# apb_ascon: IP-XACT component
VLNV emse.fr:ip:apb_ascon:0.2
Cryptographic accelerator for the Ascon128 AEAD authenticated encryption scheme.

## Parameters
APB_DW = 32
APB_AW = 10
FifoDepth = 4
DataAddrWidth = 7
DelayWidth = 16

## Bus interfaces (logical=physical port)
Clock: target tuni.fi:interface:clock:1.0
  clk=clk_in
IRQ: initiator tuni.fi:interface:IRQ:1.0
  irq=irq_1
APB: target tuni.fi:interface:APB:1.0
  PADDR=PADDR, PENABLE=PENABLE, PRDATA=PRDATA, PREADY=PREADY, PSEL=PSEL, PSLVERR=PSLVERR, PWDATA=PWDATA, PWRITE=PWRITE
Reset: target tuni.fi:interface:reset:1.0
  reset=reset_int
ss_ctrl: target tuni.fi:interface:SS_Ctrl:1.0
  clk_ctrl=ss_ctrl_1, irq_en=irq_en_1
pmod_gpio_0: initiator tuni.fi:interface:GPIO:1.0
  gpo=pmod_0_gpo, gpi=pmod_0_gpi, gpio_oe=pmod_0_gpio_oe
pmod_gpio_1: initiator tuni.fi:interface:GPIO:1.0
  gpo=pmod_1_gpo, gpi=pmod_1_gpi, gpio_oe=pmod_1_gpio_oe

## Ports
in clk_in
out irq_1
in PADDR[APB_AW-1:0]
in PENABLE
out PRDATA[APB_DW-1:0]
out PREADY
in PSEL
out PSLVERR
in PWDATA[APB_DW-1:0]
in PWRITE
in reset_int
in ss_ctrl_1[7:0]
in irq_en_1
out pmod_0_gpo[3:0]
in pmod_0_gpi[3:0]
out pmod_0_gpio_oe[3:0]
out pmod_1_gpo[3:0]
in pmod_1_gpi[3:0]
out pmod_1_gpio_oe[3:0]

## Address spaces and blocks
apb_ascon.registers: base 'h0, range 80, width 32

## Registers
Registers are 32-bit, read-write, no defined reset value unless marked. A register's access mark holds for its fields unless they carry their own. Offsets are from the block's base; lines under a group give offsets from that group; [hi:lo] are bit positions; {n}, {i} and the like mark numbered series; 'fields as' and 'values as' point back to an identical list; <NAME> marks a mode.

## apb_ascon.registers
Base 0x00000000
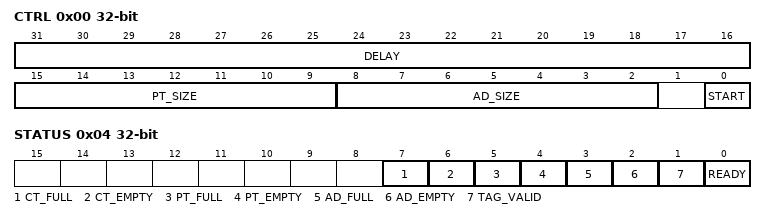
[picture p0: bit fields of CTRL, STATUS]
0x00 CTRL
  [31:16] DELAY, [15:9] PT_SIZE, [8:2] AD_SIZE, [0] START wo
0x04 STATUS ro
  [7] CT_FULL, [6] CT_EMPTY, [5] PT_FULL, [4] PT_EMPTY, [3] AD_FULL, [2] AD_EMPTY, [1] TAG_VALID, [0] READY
{0x8+4i} KEY[{i}] (i=0..3)
  [31:0] KEY
{0x18+4i} NONCE[{i}] (i=0..3)
  [31:0] NONCE
{0x28+4i} TAG[{i}] (i=0..3) ro
  [31:0] TAG
{0x38+4i} AD[{i}] (i=0..1)
  [31:0] AD
{0x40+4i} PT[{i}] (i=0..1)
  [31:0] PT
{0x48+4i} CT[{i}] (i=0..1) ro
  [31:0] CT
